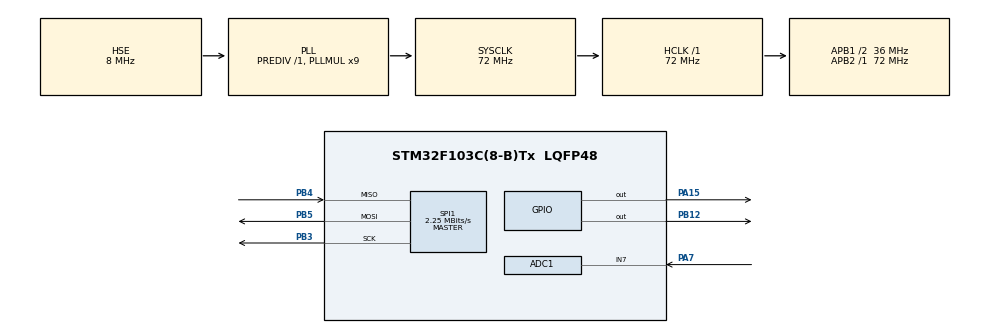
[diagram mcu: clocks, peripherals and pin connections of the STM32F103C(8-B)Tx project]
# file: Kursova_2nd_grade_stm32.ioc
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ADC1.Channel-1\#ChannelRegularConversion=ADC_CHANNEL_7
ADC1.ContinuousConvMode=ENABLE
ADC1.NbrOfConversion=1
ADC1.NbrOfConversionFlag=1
ADC1.Rank-1\#ChannelRegularConversion=1
ADC1.SamplingTime-1\#ChannelRegularConversion=ADC_SAMPLETIME_1CYCLE_5
ADC1.master=1
Dma.Request0=SPI1_TX
Dma.SPI1_TX.0.Direction=DMA_MEMORY_TO_PERIPH
Dma.SPI1_TX.0.Instance=DMA1_Channel3
Dma.SPI1_TX.0.MemDataAlignment=DMA_MDATAALIGN_BYTE
Dma.SPI1_TX.0.MemInc=DMA_MINC_ENABLE
Dma.SPI1_TX.0.Mode=DMA_NORMAL
Dma.SPI1_TX.0.PeriphDataAlignment=DMA_PDATAALIGN_BYTE
Dma.SPI1_TX.0.PeriphInc=DMA_PINC_DISABLE
Dma.SPI1_TX.0.Priority=DMA_PRIORITY_LOW
Mcu.Family=STM32F1
Mcu.Name=STM32F103C(8-B)Tx
Mcu.Package=LQFP48
NVIC.DMA1_Channel3_IRQn=true\:0\:0\:false\:false\:true\:false\:true\:true
NVIC.PriorityGroup=NVIC_PRIORITYGROUP_4
PA15.Signal=GPIO_Output
PA7.Signal=ADCx_IN7
PB12.Signal=GPIO_Output
PB3.Mode=Full_Duplex_Master
PB3.Signal=SPI1_SCK
PB4.Mode=Full_Duplex_Master
PB4.Signal=SPI1_MISO
PB5.Mode=Full_Duplex_Master
PB5.Signal=SPI1_MOSI
PD0-OSC_IN.Mode=HSE-External-Oscillator
PD0-OSC_IN.Signal=RCC_OSC_IN
PD1-OSC_OUT.Mode=HSE-External-Oscillator
PD1-OSC_OUT.Signal=RCC_OSC_OUT
ProjectManager.HeapSize=0x200
ProjectManager.StackSize=0x400
ProjectManager.TargetToolchain=STM32CubeIDE
RCC.ADCPresc=RCC_ADCPCLK2_DIV6
RCC.AHBFreq_Value=72000000
RCC.APB1CLKDivider=RCC_HCLK_DIV2
RCC.APB1Freq_Value=36000000
RCC.APB1TimFreq_Value=72000000
RCC.APB2Freq_Value=72000000
RCC.APB2TimFreq_Value=72000000
RCC.HCLKFreq_Value=72000000
RCC.PLLMUL=RCC_PLL_MUL9
RCC.PLLSourceVirtual=RCC_PLLSOURCE_HSE
RCC.SYSCLKFreq_VALUE=72000000
RCC.SYSCLKSource=RCC_SYSCLKSOURCE_PLLCLK
RCC.USBFreq_Value=72000000
SH.ADCx_IN7.0=ADC1_IN7,IN7
SPI1.BaudRatePrescaler=SPI_BAUDRATEPRESCALER_32
SPI1.CalculateBaudRate=2.25 MBits/s
SPI1.Direction=SPI_DIRECTION_2LINES
SPI1.Mode=SPI_MODE_MASTER
SPI1.VirtualType=VM_MASTER
VP_SYS_VS_ND.Mode=No_Debug
board=custom

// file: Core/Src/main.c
/* USER CODE BEGIN Header */
/**
  ******************************************************************************
  * @file           : main.c
  * @brief          : Main program body
  ******************************************************************************
  * @attention
  *
  * Copyright (c) 2025 STMicroelectronics.
  * All rights reserved.
  *
  * This software is licensed under terms that can be found in the LICENSE file
  * in the root directory of this software component.
  * If no LICENSE file comes with this software, it is provided AS-IS.
  *
  ******************************************************************************
  */
/* USER CODE END Header */
#include "main.h"

ADC_HandleTypeDef hadc1;

SPI_HandleTypeDef hspi1;
DMA_HandleTypeDef hdma_spi1_tx;

/* USER CODE BEGIN PV */

uint8_t SPI_TxBuff[RSLTS_BUFF_SIZE] = {0};
uint8_t SPI1_Rx_CmdBuff = 0;

/* USER CODE END PV */

void SystemClock_Config(void);
static void MX_GPIO_Init(void);
static void MX_DMA_Init(void);
static void MX_ADC1_Init(void);
static void MX_SPI1_Init(void);

int main(void)
{

  /* USER CODE BEGIN 1 */

  //this variable is for summing results to get the average number
  uint32_t sum = 0;
  // pointer for writing 16 bits in the SPI buffer instead of 8
  uint16_t* pwriteAVG = (uint16_t*)SPI_TxBuff;

//	for testing SPI transactions
//  uint16_t test[] = {1, 2, 3, 4, 5, 6, 7, 8, 9, 10, 11, 12, 13, 14, 15, 16, 17, 18, 19, 20, 21,
//		  	  	  	  22, 23, 24, 25, 26, 27, 28, 29, 30, 31, 32};

  /* USER CODE END 1 */

  /* MCU Configuration--------------------------------------------------------*/

  /* Reset of all peripherals, Initializes the Flash interface and the Systick. */
  HAL_Init();

  /* Configure the system clock */
  SystemClock_Config();

  /* Initialize all configured peripherals */
  MX_GPIO_Init();
  MX_DMA_Init();
  MX_ADC1_Init();
  MX_SPI1_Init();
  /* USER CODE BEGIN 2 */

  HAL_ADCEx_Calibration_Start(&hadc1);
  HAL_ADC_Start(&hadc1);

  /* USER CODE END 2 */

  /* Infinite loop */
  /* USER CODE BEGIN WHILE */

  while (1)
  {
	  for (uint16_t ConvsCount = 0; ConvsCount < RSLTS_PER_BUFF; ++ConvsCount) {
		  for (uint16_t i = 0; i < CONVS_FOR_AVG; ++i) {
			  HAL_ADC_PollForConversion(&hadc1, 1);
			  sum += HAL_ADC_GetValue(&hadc1);
		  }

		  *(pwriteAVG + ConvsCount) = (uint16_t)(sum / CONVS_FOR_AVG);
		  sum = 0;
	  }

	  SPI1_SendData((uint8_t*)(&SPI_TxBuff), RSLTS_BUFF_SIZE, SEND_TIMEOUT);

    /* USER CODE END WHILE */

  }
}

void SystemClock_Config(void)
{
  RCC_OscInitTypeDef RCC_OscInitStruct = {0};
  RCC_ClkInitTypeDef RCC_ClkInitStruct = {0};
  RCC_PeriphCLKInitTypeDef PeriphClkInit = {0};

  /** Initializes the RCC Oscillators according to the specified parameters
  * in the RCC_OscInitTypeDef structure.
  */
  RCC_OscInitStruct.OscillatorType = RCC_OSCILLATORTYPE_HSE;
  RCC_OscInitStruct.HSEState = RCC_HSE_ON;
  RCC_OscInitStruct.HSEPredivValue = RCC_HSE_PREDIV_DIV1;
  RCC_OscInitStruct.HSIState = RCC_HSI_ON;
  RCC_OscInitStruct.PLL.PLLState = RCC_PLL_ON;
  RCC_OscInitStruct.PLL.PLLSource = RCC_PLLSOURCE_HSE;
  RCC_OscInitStruct.PLL.PLLMUL = RCC_PLL_MUL9;
  if (HAL_RCC_OscConfig(&RCC_OscInitStruct) != HAL_OK)
  {
    Error_Handler();
  }

  /** Initializes the CPU, AHB and APB buses clocks
  */
  RCC_ClkInitStruct.ClockType = RCC_CLOCKTYPE_HCLK|RCC_CLOCKTYPE_SYSCLK
                              |RCC_CLOCKTYPE_PCLK1|RCC_CLOCKTYPE_PCLK2;
  RCC_ClkInitStruct.SYSCLKSource = RCC_SYSCLKSOURCE_PLLCLK;
  RCC_ClkInitStruct.AHBCLKDivider = RCC_SYSCLK_DIV1;
  RCC_ClkInitStruct.APB1CLKDivider = RCC_HCLK_DIV2;
  RCC_ClkInitStruct.APB2CLKDivider = RCC_HCLK_DIV1;

  if (HAL_RCC_ClockConfig(&RCC_ClkInitStruct, FLASH_LATENCY_2) != HAL_OK)
  {
    Error_Handler();
  }
  PeriphClkInit.PeriphClockSelection = RCC_PERIPHCLK_ADC;
  PeriphClkInit.AdcClockSelection = RCC_ADCPCLK2_DIV6;
  if (HAL_RCCEx_PeriphCLKConfig(&PeriphClkInit) != HAL_OK)
  {
    Error_Handler();
  }
}

static void MX_ADC1_Init(void)
{

  ADC_ChannelConfTypeDef sConfig = {0};

  /** Common config
  */
  hadc1.Instance = ADC1;
  hadc1.Init.ScanConvMode = ADC_SCAN_DISABLE;
  hadc1.Init.ContinuousConvMode = ENABLE;
  hadc1.Init.DiscontinuousConvMode = DISABLE;
  hadc1.Init.ExternalTrigConv = ADC_SOFTWARE_START;
  hadc1.Init.DataAlign = ADC_DATAALIGN_RIGHT;
  hadc1.Init.NbrOfConversion = 1;
  if (HAL_ADC_Init(&hadc1) != HAL_OK)
  {
    Error_Handler();
  }

  /** Configure Regular Channel
  */
  sConfig.Channel = ADC_CHANNEL_7;
  sConfig.Rank = ADC_REGULAR_RANK_1;
  sConfig.SamplingTime = ADC_SAMPLETIME_1CYCLE_5;
  if (HAL_ADC_ConfigChannel(&hadc1, &sConfig) != HAL_OK)
  {
    Error_Handler();
  }

}

static void MX_SPI1_Init(void)
{

  /* SPI1 parameter configuration*/
  hspi1.Instance = SPI1;
  hspi1.Init.Mode = SPI_MODE_MASTER;
  hspi1.Init.Direction = SPI_DIRECTION_2LINES;
  hspi1.Init.DataSize = SPI_DATASIZE_8BIT;
  hspi1.Init.CLKPolarity = SPI_POLARITY_LOW;
  hspi1.Init.CLKPhase = SPI_PHASE_1EDGE;
  hspi1.Init.NSS = SPI_NSS_SOFT;
  hspi1.Init.BaudRatePrescaler = SPI_BAUDRATEPRESCALER_32;
  hspi1.Init.FirstBit = SPI_FIRSTBIT_MSB;
  hspi1.Init.TIMode = SPI_TIMODE_DISABLE;
  hspi1.Init.CRCCalculation = SPI_CRCCALCULATION_DISABLE;
  hspi1.Init.CRCPolynomial = 10;
  if (HAL_SPI_Init(&hspi1) != HAL_OK)
  {
    Error_Handler();
  }

}

static void MX_DMA_Init(void)
{

  /* DMA controller clock enable */
  __HAL_RCC_DMA1_CLK_ENABLE();

  /* DMA interrupt init */
  /* DMA1_Channel3_IRQn interrupt configuration */
  HAL_NVIC_SetPriority(DMA1_Channel3_IRQn, 0, 0);
  HAL_NVIC_EnableIRQ(DMA1_Channel3_IRQn);

}

static void MX_GPIO_Init(void)
{
  GPIO_InitTypeDef GPIO_InitStruct = {0};

  /* GPIO Ports Clock Enable */
  __HAL_RCC_GPIOD_CLK_ENABLE();
  __HAL_RCC_GPIOA_CLK_ENABLE();
  __HAL_RCC_GPIOB_CLK_ENABLE();

  /*Configure GPIO pin Output Level */
  HAL_GPIO_WritePin(GPIOB, GPIO_PIN_12, GPIO_PIN_RESET);

  /*Configure GPIO pin Output Level */
  HAL_GPIO_WritePin(GPIOA, GPIO_PIN_15, GPIO_PIN_RESET);

  /*Configure GPIO pin : PB12 */
  GPIO_InitStruct.Pin = GPIO_PIN_12;
  GPIO_InitStruct.Mode = GPIO_MODE_OUTPUT_PP;
  GPIO_InitStruct.Pull = GPIO_NOPULL;
  GPIO_InitStruct.Speed = GPIO_SPEED_FREQ_LOW;
  HAL_GPIO_Init(GPIOB, &GPIO_InitStruct);

  /*Configure GPIO pin : PA15 */
  GPIO_InitStruct.Pin = GPIO_PIN_15;
  GPIO_InitStruct.Mode = GPIO_MODE_OUTPUT_PP;
  GPIO_InitStruct.Pull = GPIO_NOPULL;
  GPIO_InitStruct.Speed = GPIO_SPEED_FREQ_LOW;
  HAL_GPIO_Init(GPIOA, &GPIO_InitStruct);

}

void Error_Handler(void)
{
  __disable_irq();
  while (1)
  {
  }
}
